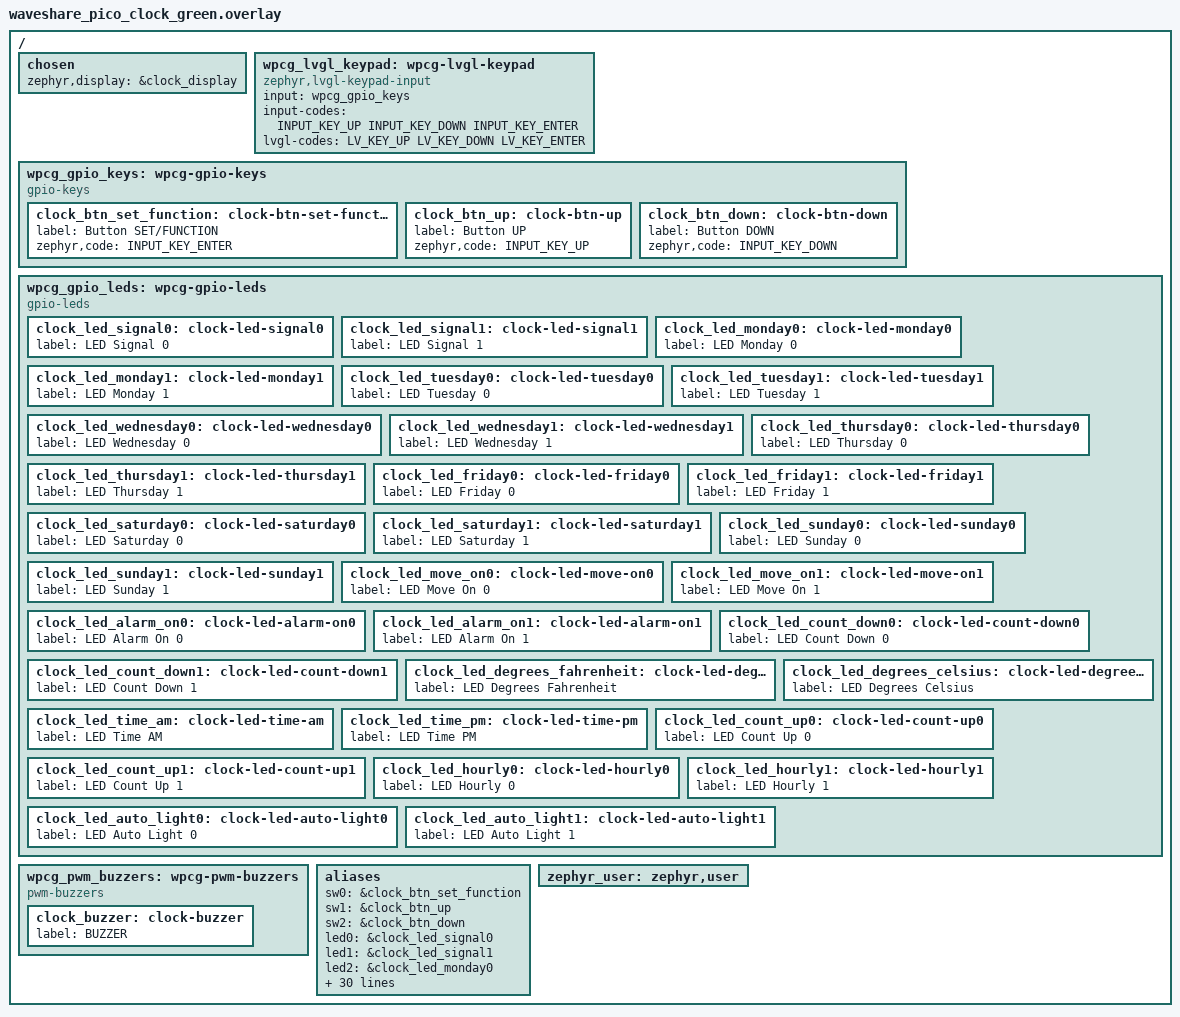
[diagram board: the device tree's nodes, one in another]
/*
 * SPDX-FileCopyrightText: Copyright (c) 2023-2026 TiaC Systems
 * SPDX-License-Identifier: Apache-2.0
 */

#include <zephyr/dt-bindings/input/input-event-codes.h>
#include <zephyr/dt-bindings/lvgl/lvgl.h>

/ {
	chosen {
		zephyr,display = &clock_display;
	};

	wpcg_lvgl_keypad: wpcg-lvgl-keypad {
		compatible = "zephyr,lvgl-keypad-input";
		status = "okay";

		input = <&wpcg_gpio_keys>;
		input-codes = <INPUT_KEY_UP INPUT_KEY_DOWN
			       INPUT_KEY_ENTER>;
		lvgl-codes = <LV_KEY_UP LV_KEY_DOWN
			      LV_KEY_ENTER>;
	};

	/delete-node/ keys;
	/delete-node/ gpio_keys;
	/delete-node/ gpio-keys;
	wpcg_gpio_keys: wpcg-gpio-keys {
		compatible = "gpio-keys";
		status = "okay";

		clock_btn_set_function: clock-btn-set-function {
			label = "Button SET/FUNCTION";
			zephyr,code = <INPUT_KEY_ENTER>;
		};
		clock_btn_up: clock-btn-up {
			label = "Button UP";
			zephyr,code = <INPUT_KEY_UP>;
		};
		clock_btn_down: clock-btn-down {
			label = "Button DOWN";
			zephyr,code = <INPUT_KEY_DOWN>;
		};
	};

	/delete-node/ leds;
	/delete-node/ gpio_leds;
	/delete-node/ gpio-leds;
	wpcg_gpio_leds: wpcg-gpio-leds {
		compatible = "gpio-leds";
		status = "okay";

		clock_led_signal0: clock-led-signal0 {
			label = "LED Signal 0";
		};
		clock_led_signal1: clock-led-signal1 {
			label = "LED Signal 1";
		};

		clock_led_monday0: clock-led-monday0 {
			label = "LED Monday 0";
		};
		clock_led_monday1: clock-led-monday1 {
			label = "LED Monday 1";
		};

		clock_led_tuesday0: clock-led-tuesday0 {
			label = "LED Tuesday 0";
		};
		clock_led_tuesday1: clock-led-tuesday1 {
			label = "LED Tuesday 1";
		};

		clock_led_wednesday0: clock-led-wednesday0 {
			label = "LED Wednesday 0";
		};
		clock_led_wednesday1: clock-led-wednesday1 {
			label = "LED Wednesday 1";
		};

		clock_led_thursday0: clock-led-thursday0 {
			label = "LED Thursday 0";
		};
		clock_led_thursday1: clock-led-thursday1 {
			label = "LED Thursday 1";
		};

		clock_led_friday0: clock-led-friday0 {
			label = "LED Friday 0";
		};
		clock_led_friday1: clock-led-friday1 {
			label = "LED Friday 1";
		};

		clock_led_saturday0: clock-led-saturday0 {
			label = "LED Saturday 0";
		};
		clock_led_saturday1: clock-led-saturday1 {
			label = "LED Saturday 1";
		};

		clock_led_sunday0: clock-led-sunday0 {
			label = "LED Sunday 0";
		};
		clock_led_sunday1: clock-led-sunday1 {
			label = "LED Sunday 1";
		};

		clock_led_move_on0: clock-led-move-on0 {
			label = "LED Move On 0";
		};
		clock_led_move_on1: clock-led-move-on1 {
			label = "LED Move On 1";
		};

		clock_led_alarm_on0: clock-led-alarm-on0 {
			label = "LED Alarm On 0";
		};
		clock_led_alarm_on1: clock-led-alarm-on1 {
			label = "LED Alarm On 1";
		};

		clock_led_count_down0: clock-led-count-down0 {
			label = "LED Count Down 0";
		};
		clock_led_count_down1: clock-led-count-down1 {
			label = "LED Count Down 1";
		};

		clock_led_degrees_fahrenheit: clock-led-degrees-fahrenheit {
			label = "LED Degrees Fahrenheit";
		};
		clock_led_degrees_celsius: clock-led-degrees-celsius {
			label = "LED Degrees Celsius";
		};

		clock_led_time_am: clock-led-time-am {
			label = "LED Time AM";
		};
		clock_led_time_pm: clock-led-time-pm {
			label = "LED Time PM";
		};

		clock_led_count_up0: clock-led-count-up0 {
			label = "LED Count Up 0";
		};
		clock_led_count_up1: clock-led-count-up1 {
			label = "LED Count Up 1";
		};

		clock_led_hourly0: clock-led-hourly0 {
			label = "LED Hourly 0";
		};
		clock_led_hourly1: clock-led-hourly1 {
			label = "LED Hourly 1";
		};

		clock_led_auto_light0: clock-led-auto-light0 {
			label = "LED Auto Light 0";
		};
		clock_led_auto_light1: clock-led-auto-light1 {
			label = "LED Auto Light 1";
		};
	};

	/delete-node/ pwm_leds;
	/delete-node/ pwm-leds;

	/delete-node/ buzzers;
	/delete-node/ pwm_buzzers;
	/delete-node/ pwm-buzzers;
	wpcg_pwm_buzzers: wpcg-pwm-buzzers {
		compatible = "pwm-buzzers";
		status = "okay";

		clock_buzzer: clock-buzzer {
			label = "BUZZER";
		};
	};

	aliases {
		/delete-property/ sw0;
		sw0 = &clock_btn_set_function;
		sw1 = &clock_btn_up;
		sw2 = &clock_btn_down;
		/delete-property/ led0;
		led0 = &clock_led_signal0;
		led1 = &clock_led_signal1;
		led2 = &clock_led_monday0;
		led3 = &clock_led_monday1;
		led4 = &clock_led_tuesday0;
		led5 = &clock_led_tuesday1;
		led6 = &clock_led_wednesday0;
		led7 = &clock_led_wednesday1;
		led8 = &clock_led_thursday0;
		led9 = &clock_led_thursday1;
		led10 = &clock_led_friday0;
		led11 = &clock_led_friday1;
		led12 = &clock_led_saturday0;
		led13 = &clock_led_saturday1;
		led14 = &clock_led_sunday0;
		led15 = &clock_led_sunday1;
		led16 = &clock_led_move_on0;
		led17 = &clock_led_move_on1;
		led18 = &clock_led_alarm_on0;
		led19 = &clock_led_alarm_on1;
		led20 = &clock_led_count_down0;
		led21 = &clock_led_count_down1;
		led22 = &clock_led_degrees_fahrenheit;
		led23 = &clock_led_degrees_celsius;
		led24 = &clock_led_time_am;
		led25 = &clock_led_time_pm;
		led26 = &clock_led_count_up0;
		led27 = &clock_led_count_up1;
		led28 = &clock_led_hourly0;
		led29 = &clock_led_hourly1;
		led30 = &clock_led_auto_light0;
		led31 = &clock_led_auto_light1;
		/delete-property/ pwm-led0;
		pwm-buzzer0 = &clock_buzzer;
	};

	zephyr_user: zephyr,user {
		/delete-property/ io-channels;
	};
};
